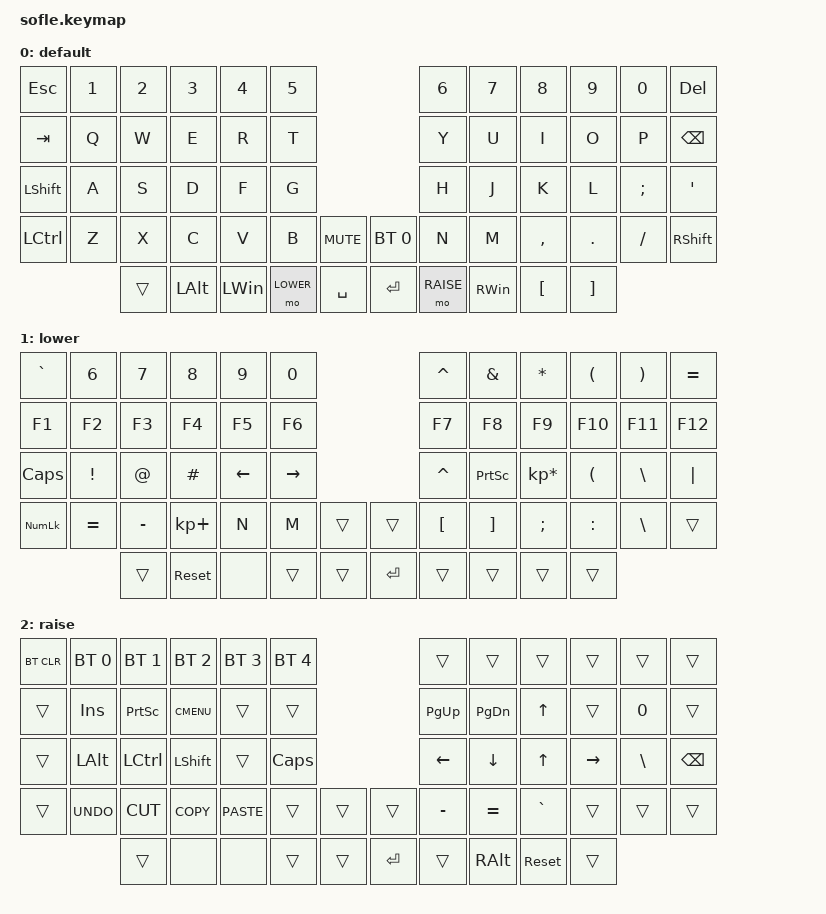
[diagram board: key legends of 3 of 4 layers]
/*
 * Copyright (c) 2020 The ZMK Contributors
 *
 * SPDX-License-Identifier: MIT
 */

#include <behaviors.dtsi>
#include <dt-bindings/zmk/bt.h>
#include <dt-bindings/zmk/ext_power.h>
#include <dt-bindings/zmk/keys.h>
#include <dt-bindings/zmk/rgb.h>
#include <dt-bindings/zmk/led_map.h>
#include <dt-bindings/led/led.h>

#define BASE 0
#define LOWER 1
#define RAISE 2
#define ADJUST 3

&pinctrl {
    spi3_default: spi3_default {
        group1 {
            psels = <NRF_PSEL(SPIM_MOSI, 0, 6)>;
        };
    };

    spi3_sleep: spi3_sleep {
        group1 {
            psels = <NRF_PSEL(SPIM_MOSI, 0, 6)>;
            low-power-enable;
        };
    };
};

&spi3 {
    compatible = "nordic,nrf-spim";
    status = "okay";
    pinctrl-0 = <&spi3_default>;
    pinctrl-1 = <&spi3_sleep>;
    pinctrl-names = "default", "sleep";

    led_strip: ws2812@0 {
        compatible = "worldsemi,ws2812-spi";
        reg = <0>;
        spi-max-frequency = <4000000>;
        chain-length = <72>;
        spi-one-frame = <0x70>;
        spi-zero-frame = <0x40>;
        color-mapping = <LED_COLOR_ID_GREEN LED_COLOR_ID_RED LED_COLOR_ID_BLUE>;
    };
};

/ {
    chosen {
        zmk,underglow = &led_strip;
    };

    led_map_config: led-map {
        compatible = "zmk,led-map";
        led-strip = <&led_strip>;
    };

    // Activate ADJUST layer by pressing raise and lower

    conditional_layers {
        compatible = "zmk,conditional-layers";

        adjust_layer {
            if-layers = <LOWER RAISE>;
            then-layer = <ADJUST>;
        };
    };

    macros {
        rgb_calm: rgb_calm {
            compatible = "zmk,behavior-macro";
            #binding-cells = <0>;
            wait-ms = <10>;
            tap-ms = <10>;
            bindings =
                <&macro_tap &rgb_ug RGB_ON>,
                <&macro_tap &rgb_ug RGB_EFS_CMD 0>,
                <&macro_tap &rgb_ug RGB_COLOR_HSB(190,100,35)>;
        };

        rgb_focus: rgb_focus {
            compatible = "zmk,behavior-macro";
            #binding-cells = <0>;
            wait-ms = <10>;
            tap-ms = <10>;
            bindings =
                <&macro_tap &rgb_ug RGB_ON>,
                <&macro_tap &rgb_ug RGB_EFS_CMD 0>,
                <&macro_tap &rgb_ug RGB_COLOR_HSB(35,100,40)>;
        };

        rgb_alert: rgb_alert {
            compatible = "zmk,behavior-macro";
            #binding-cells = <0>;
            wait-ms = <10>;
            tap-ms = <10>;
            bindings =
                <&macro_tap &rgb_ug RGB_ON>,
                <&macro_tap &rgb_ug RGB_EFS_CMD 0>,
                <&macro_tap &rgb_ug RGB_COLOR_HSB(0,100,40)>;
        };

        rgb_dim: rgb_dim {
            compatible = "zmk,behavior-macro";
            #binding-cells = <0>;
            wait-ms = <10>;
            tap-ms = <10>;
            bindings =
                <&macro_tap &rgb_ug RGB_ON>,
                <&macro_tap &rgb_ug RGB_EFS_CMD 0>,
                <&macro_tap &rgb_ug RGB_COLOR_HSB(0,0,15)>;
        };

        rgb_red: rgb_red {
            compatible = "zmk,behavior-macro";
            #binding-cells = <0>;
            wait-ms = <10>;
            tap-ms = <10>;
            bindings =
                <&macro_tap &rgb_ug RGB_ON>,
                <&macro_tap &rgb_ug RGB_EFS_CMD 0>,
                <&macro_tap &rgb_ug RGB_COLOR_HSB(0,100,45)>;
        };

        rgb_orange: rgb_orange {
            compatible = "zmk,behavior-macro";
            #binding-cells = <0>;
            wait-ms = <10>;
            tap-ms = <10>;
            bindings =
                <&macro_tap &rgb_ug RGB_ON>,
                <&macro_tap &rgb_ug RGB_EFS_CMD 0>,
                <&macro_tap &rgb_ug RGB_COLOR_HSB(25,100,45)>;
        };

        rgb_yellow: rgb_yellow {
            compatible = "zmk,behavior-macro";
            #binding-cells = <0>;
            wait-ms = <10>;
            tap-ms = <10>;
            bindings =
                <&macro_tap &rgb_ug RGB_ON>,
                <&macro_tap &rgb_ug RGB_EFS_CMD 0>,
                <&macro_tap &rgb_ug RGB_COLOR_HSB(55,100,45)>;
        };

        rgb_green: rgb_green {
            compatible = "zmk,behavior-macro";
            #binding-cells = <0>;
            wait-ms = <10>;
            tap-ms = <10>;
            bindings =
                <&macro_tap &rgb_ug RGB_ON>,
                <&macro_tap &rgb_ug RGB_EFS_CMD 0>,
                <&macro_tap &rgb_ug RGB_COLOR_HSB(120,100,40)>;
        };

        rgb_cyan: rgb_cyan {
            compatible = "zmk,behavior-macro";
            #binding-cells = <0>;
            wait-ms = <10>;
            tap-ms = <10>;
            bindings =
                <&macro_tap &rgb_ug RGB_ON>,
                <&macro_tap &rgb_ug RGB_EFS_CMD 0>,
                <&macro_tap &rgb_ug RGB_COLOR_HSB(185,100,40)>;
        };

        rgb_blue: rgb_blue {
            compatible = "zmk,behavior-macro";
            #binding-cells = <0>;
            wait-ms = <10>;
            tap-ms = <10>;
            bindings =
                <&macro_tap &rgb_ug RGB_ON>,
                <&macro_tap &rgb_ug RGB_EFS_CMD 0>,
                <&macro_tap &rgb_ug RGB_COLOR_HSB(225,100,40)>;
        };

        rgb_purple: rgb_purple {
            compatible = "zmk,behavior-macro";
            #binding-cells = <0>;
            wait-ms = <10>;
            tap-ms = <10>;
            bindings =
                <&macro_tap &rgb_ug RGB_ON>,
                <&macro_tap &rgb_ug RGB_EFS_CMD 0>,
                <&macro_tap &rgb_ug RGB_COLOR_HSB(275,100,40)>;
        };

        rgb_pink: rgb_pink {
            compatible = "zmk,behavior-macro";
            #binding-cells = <0>;
            wait-ms = <10>;
            tap-ms = <10>;
            bindings =
                <&macro_tap &rgb_ug RGB_ON>,
                <&macro_tap &rgb_ug RGB_EFS_CMD 0>,
                <&macro_tap &rgb_ug RGB_COLOR_HSB(320,100,45)>;
        };

        rgb_white: rgb_white {
            compatible = "zmk,behavior-macro";
            #binding-cells = <0>;
            wait-ms = <10>;
            tap-ms = <10>;
            bindings =
                <&macro_tap &rgb_ug RGB_ON>,
                <&macro_tap &rgb_ug RGB_EFS_CMD 0>,
                <&macro_tap &rgb_ug RGB_COLOR_HSB(0,0,45)>;
        };

        rgb_breathe: rgb_breathe {
            compatible = "zmk,behavior-macro";
            #binding-cells = <0>;
            wait-ms = <10>;
            tap-ms = <10>;
            bindings =
                <&macro_tap &rgb_ug RGB_ON>,
                <&macro_tap &rgb_ug RGB_EFS_CMD 1>,
                <&macro_tap &rgb_ug RGB_COLOR_HSB(275,100,35)>;
        };

        rgb_breathe_red: rgb_breathe_red {
            compatible = "zmk,behavior-macro";
            #binding-cells = <0>;
            wait-ms = <10>;
            tap-ms = <10>;
            bindings =
                <&macro_tap &rgb_ug RGB_ON>,
                <&macro_tap &rgb_ug RGB_EFS_CMD 1>,
                <&macro_tap &rgb_ug RGB_COLOR_HSB(0,100,40)>;
        };

        rgb_breathe_green: rgb_breathe_green {
            compatible = "zmk,behavior-macro";
            #binding-cells = <0>;
            wait-ms = <10>;
            tap-ms = <10>;
            bindings =
                <&macro_tap &rgb_ug RGB_ON>,
                <&macro_tap &rgb_ug RGB_EFS_CMD 1>,
                <&macro_tap &rgb_ug RGB_COLOR_HSB(120,100,35)>;
        };

        rgb_breathe_blue: rgb_breathe_blue {
            compatible = "zmk,behavior-macro";
            #binding-cells = <0>;
            wait-ms = <10>;
            tap-ms = <10>;
            bindings =
                <&macro_tap &rgb_ug RGB_ON>,
                <&macro_tap &rgb_ug RGB_EFS_CMD 1>,
                <&macro_tap &rgb_ug RGB_COLOR_HSB(225,100,35)>;
        };

        rgb_breathe_white: rgb_breathe_white {
            compatible = "zmk,behavior-macro";
            #binding-cells = <0>;
            wait-ms = <10>;
            tap-ms = <10>;
            bindings =
                <&macro_tap &rgb_ug RGB_ON>,
                <&macro_tap &rgb_ug RGB_EFS_CMD 1>,
                <&macro_tap &rgb_ug RGB_COLOR_HSB(0,0,35)>;
        };

        rgb_spectrum: rgb_spectrum {
            compatible = "zmk,behavior-macro";
            #binding-cells = <0>;
            wait-ms = <10>;
            tap-ms = <10>;
            bindings =
                <&macro_tap &rgb_ug RGB_ON>,
                <&macro_tap &rgb_ug RGB_EFS_CMD 2>;
        };

        rgb_swirl: rgb_swirl {
            compatible = "zmk,behavior-macro";
            #binding-cells = <0>;
            wait-ms = <10>;
            tap-ms = <10>;
            bindings =
                <&macro_tap &rgb_ug RGB_ON>,
                <&macro_tap &rgb_ug RGB_EFS_CMD 3>;
        };

        rgb_spreadish: rgb_spreadish {
            compatible = "zmk,behavior-macro";
            #binding-cells = <0>;
            wait-ms = <10>;
            tap-ms = <10>;
            bindings =
                <&macro_tap &rgb_ug RGB_ON>,
                <&macro_tap &rgb_ug RGB_EFS_CMD 3>,
                <&macro_tap &rgb_ug RGB_COLOR_HSB(190,100,45)>,
                <&macro_tap &rgb_ug RGB_SPI>,
                <&macro_tap &rgb_ug RGB_SPI>;
        };

        rgb_party: rgb_party {
            compatible = "zmk,behavior-macro";
            #binding-cells = <0>;
            wait-ms = <10>;
            tap-ms = <10>;
            bindings =
                <&macro_tap &rgb_ug RGB_ON>,
                <&macro_tap &rgb_ug RGB_EFS_CMD 2>,
                <&macro_tap &rgb_ug RGB_COLOR_HSB(320,100,45)>;
        };

        rgb_night: rgb_night {
            compatible = "zmk,behavior-macro";
            #binding-cells = <0>;
            wait-ms = <10>;
            tap-ms = <10>;
            bindings =
                <&macro_tap &rgb_ug RGB_ON>,
                <&macro_tap &rgb_ug RGB_EFS_CMD 1>,
                <&macro_tap &rgb_ug RGB_COLOR_HSB(225,100,18)>;
        };

        rgb_matrix: rgb_matrix {
            compatible = "zmk,behavior-macro";
            #binding-cells = <0>;
            wait-ms = <10>;
            tap-ms = <10>;
            bindings =
                <&macro_tap &rgb_ug RGB_ON>,
                <&macro_tap &rgb_ug RGB_EFS_CMD 3>,
                <&macro_tap &rgb_ug RGB_COLOR_HSB(120,100,35)>;
        };

    };

    keymap {
        compatible = "zmk,keymap";

        default_layer {
            label = "default";

            // ------------------------------------------------------------------------------------------------------------
            // |   `   |  1  |  2  |  3   |  4   |  5   |                   |  6   |  7    |  8    |  9   |   0   |       |
            // |  ESC  |  Q  |  W  |  E   |  R   |  T   |                   |  Y   |  U    |  I    |  O   |   P   | BKSPC |
            // |  TAB  |  A  |  S  |  D   |  F   |  G   |                   |  H   |  J    |  K    |  L   |   ;   |   '   |
            // | SHIFT |  Z  |  X  |  C   |  V   |  B   |  MUTE  |  |       |  N   |  M    |  ,    |  .   |   /   | SHIFT |
            //               | GUI | ALT  | CTRL | LOWER|  ENTER |  | SPACE | RAISE| CTRL  | ALT   | GUI  |

            bindings = <
&kp ESC         &kp N1  &kp N2  &kp N3        &kp N4        &kp N5                                 &kp N6     &kp N7         &kp N8            &kp N9             &kp N0    &kp DELETE
&kp TAB         &kp Q   &kp W   &kp E         &kp R         &kp T                                  &kp Y      &kp U          &kp I             &kp O              &kp P     &kp BACKSPACE
&kp LEFT_SHIFT  &kp A   &kp S   &kp D         &kp F         &kp G                                  &kp H      &kp J          &kp K             &kp L              &kp SEMI  &kp SQT
&kp LCTRL       &kp Z   &kp X   &kp C         &kp V         &kp B      &kp C_MUTE    &bt BT_SEL 0  &kp N      &kp M          &kp COMMA         &kp DOT            &kp FSLH  &kp RSHFT
                        &trans  &kp LEFT_ALT  &kp LEFT_WIN  &mo LOWER  &kp SPACE     &kp ENTER     &mo RAISE  &kp RIGHT_WIN  &kp LEFT_BRACKET  &kp RIGHT_BRACKET
            >;

            sensor-bindings = <&inc_dec_kp C_VOL_UP C_VOL_DN &inc_dec_kp PG_UP PG_DN>;
        };

        lower_layer {
            label = "lower";

            // TODO: Some binds are waiting for shifted keycode support.
            // ------------------------------------------------------------------------------------------------------------
            // |       |  F1 |  F2 |  F3  |  F4  |  F5  |                   |  F6  |  F7   |  F8   |  F9  |  F10  |  F11  |
            // |   `   |  1  |  2  |  3   |  4   |  5   |                   |  6   |  7    |  8    |  9   |   0   |  F12  |
            // |       |  !  |  @  |  #   |  $   |  %   |                   |  ^   |  &    |  *    |  (   |   )   |   |   |
            // |       |  =  |  -  |  +   |  {   |  }   |        |  |       |  [   |  ]    |  ;    |  :   |   \   |       |
            //               |     |      |      |      |        |  |       |      |       |       |      |

            bindings = <
&kp GRAVE       &kp NUMBER_6  &kp NUMBER_7  &kp N8       &kp NUMBER_9  &kp N0                          &kp CARET  &kp AMPERSAND    &kp ASTERISK     &kp LEFT_PARENTHESIS  &kp RIGHT_PARENTHESIS  &kp EQUAL
&kp F1          &kp F2        &kp F3        &kp F4       &kp F5        &kp F6                          &kp F7     &kp F8           &kp F9           &kp F10               &kp F11                &kp F12
&kp CAPSLOCK    &kp EXCL      &kp AT        &kp HASH     &kp LEFT      &kp RIGHT                       &kp CARET  &kp PRINTSCREEN  &kp KP_MULTIPLY  &kp LPAR              &kp BACKSLASH          &kp PIPE
&kp KP_NUMLOCK  &kp EQUAL     &kp MINUS     &kp KP_PLUS  &kp N         &kp M      &trans    &trans     &kp LBKT   &kp RBKT         &kp SEMI         &kp COLON             &kp BSLH               &trans
                              &trans        &sys_reset   &none         &trans     &trans    &kp ENTER  &trans     &trans           &trans           &trans
            >;

            sensor-bindings =
                <&inc_dec_kp C_VOL_UP C_VOL_DN>,
                <&inc_dec_kp C_BRIGHTNESS_INC C_BRIGHTNESS_DEC>;
        };

        raise_layer {
            label = "raise";

            // ------------------------------------------------------------------------------------------------------------
            // | BTCLR | BT1  | BT2  |  BT3  |  BT4  |  BT5 |                |      |      |       |      |       |       |
            // |       | INS  | PSCR | GUI   |       |      |                | PGUP |      |   ^   |      |       |       |
            // |       | ALT  | CTRL | SHIFT |       | CAPS |                | PGDN |   <- |   v   |  ->  |  DEL  | BKSPC |
            // |       | UNDO | CUT  | COPY  | PASTE |      |      |  |      |      |      |       |      |       |       |
            //                |      |       |       |      |      |  |      |      |      |       |      |

            bindings = <
&bt BT_CLR  &bt BT_SEL 0  &bt BT_SEL 1  &bt BT_SEL 2  &bt BT_SEL 3  &bt BT_SEL 4                       &trans          &trans          &trans        &trans     &trans         &trans
&trans      &kp INS       &kp PSCRN     &kp K_CMENU   &trans        &trans                             &kp PG_UP       &kp PAGE_DOWN   &kp UP        &trans     &kp N0         &trans
&trans      &kp LALT      &kp LCTRL     &kp LSHFT     &trans        &kp CLCK                           &kp LEFT_ARROW  &kp DOWN_ARROW  &kp UP_ARROW  &kp RIGHT  &kp BACKSLASH  &kp BSPC
&trans      &kp K_UNDO    &kp K_CUT     &kp K_COPY    &kp K_PASTE   &trans        &trans    &trans     &kp MINUS       &kp EQUAL       &kp GRAVE     &trans     &trans         &trans
                          &trans        &none         &none         &trans        &trans    &kp ENTER  &trans          &kp RALT        &sys_reset    &trans
            >;

            sensor-bindings = <&inc_dec_kp C_VOL_UP C_VOL_DN &inc_dec_kp PG_UP PG_DN>;
        };

        adjust_layer {
            // ----------------------------------------------------------------------------------------------------------------------------
            // | BTCLR  |  BT1    |  BT2    |   BT3   |   BT4   |   BT5   |                  |      |      |       |      |       |       |
            // | EXTPWR | RGB_HUD | RGB_HUI | RGB_SAD | RGB_SAI | RGB_EFF |                  |      |      |       |      |       |       |
            // |        | RGB_BRD | RGB_BRI |         |         |         |                  |      |      |       |      |       |       |
            // |        |         |         |         |         |         | RGB_TOG | |      |      |      |       |      |       |       |
            //                    |         |         |         |         |         | |      |      |      |       |      |

            label = "adjust";
            bindings = <
&rgb_red           &rgb_orange      &rgb_yellow      &rgb_green      &rgb_cyan      &rgb_blue                               &rgb_purple    &rgb_pink       &rgb_white       &rgb_dim       &rgb_spreadish  &rgb_party
&ext_power EP_TOG  &rgb_ug RGB_HUD  &rgb_ug RGB_HUI  &rgb_ug RGB_SAD  &rgb_ug RGB_SAI  &rgb_ug RGB_EFF                         &rgb_calm      &rgb_focus      &rgb_alert       &rgb_breathe   &rgb_spectrum   &rgb_swirl
&rgb_ug RGB_OFF    &rgb_ug RGB_BRD  &rgb_ug RGB_BRI  &rgb_ug RGB_SPD  &rgb_ug RGB_SPI  &rgb_ug RGB_EFR                         &rgb_night     &rgb_matrix     &rgb_breathe_red &rgb_breathe_green &rgb_breathe_blue &rgb_breathe_white
&led_map LED_MAP_ON &led_map LED_MAP_TOG &led_map LED_MAP_EFS_CMD 4 &led_map LED_MAP_EFS_CMD 5 &led_map LED_MAP_EFS_CMD 6 &led_map LED_MAP_EFS_CMD 7 &led_map LED_MAP_TOG &led_map LED_MAP_EFR &led_map LED_MAP_EFF &led_map LED_MAP_SPD &led_map LED_MAP_SPI &led_map LED_MAP_BAT &led_map LED_MAP_OFF
                                    &none            &none            &none            &none            &none              &none  &none  &none  &none  &none
            >;
        };
    };
};
